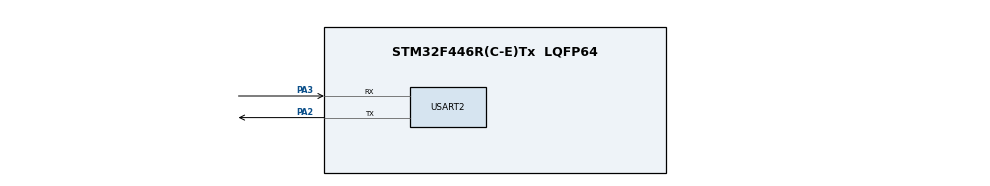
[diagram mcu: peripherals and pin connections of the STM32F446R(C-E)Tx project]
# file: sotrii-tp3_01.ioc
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FREERTOS.Tasks01=defaultTask,24,128,StartDefaultTask,Default,NULL,Dynamic,NULL,NULL
FREERTOS.configCHECK_FOR_STACK_OVERFLOW=0
FREERTOS.configUSE_IDLE_HOOK=0
FREERTOS.configUSE_PREEMPTION=0
FREERTOS.configUSE_TICK_HOOK=0
FREERTOS.configUSE_TIMERS=1
Mcu.Family=STM32F4
Mcu.Name=STM32F446R(C-E)Tx
Mcu.Package=LQFP64
NVIC.PriorityGroup=NVIC_PRIORITYGROUP_4
PA2.Mode=Asynchronous
PA2.Signal=USART2_TX
PA3.Mode=Asynchronous
PA3.Signal=USART2_RX
ProjectManager.HeapSize=0x200
ProjectManager.StackSize=0x400
ProjectManager.TargetToolchain=STM32CubeIDE
RCC.CortexFreq_Value=16000000
RCC.USBFreq_Value=96000000
RCC.VCOOutputFreq_Value=192000000
USART2.VirtualMode=VM_ASYNC
VP_FREERTOS_VS_CMSIS_V2.Mode=CMSIS_V2
VP_TIM6_VS_ClockSourceINT.Mode=Enable_Timer
board=custom

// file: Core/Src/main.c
/* USER CODE BEGIN Header */

/**

******************************************************************************

* @file : main.c

* @brief : Main program body

******************************************************************************

*/

/* USER CODE END Header */
#include "main.h"
#include "cmsis_os.h"

/* USER CODE BEGIN Includes */

#include "app.h"
#include "dwt.h"
#include "logger.h"

/* USER CODE END Includes */

TIM_HandleTypeDef htim6;

UART_HandleTypeDef huart2;

/* Definitions for defaultTask */
osThreadId_t defaultTaskHandle;
const osThreadAttr_t defaultTask_attributes = {
  .name = "defaultTask",
  .stack_size = 128 * 4,
  .priority = (osPriority_t) osPriorityNormal,
};

void SystemClock_Config(void);
static void MX_GPIO_Init(void);
static void MX_TIM6_Init(void);
static void MX_USART2_UART_Init(void);
void StartDefaultTask(void *argument);

/* USER CODE BEGIN PFP */

extern void initialise_monitor_handles(void);

/* USER CODE END PFP */

int main(void)
{

  /* USER CODE BEGIN 1 */
  initialise_monitor_handles();

  /* USER CODE END 1 */

  /* MCU Configuration--------------------------------------------------------*/

  /* Reset of all peripherals, Initializes the Flash interface and the Systick. */
  HAL_Init();

  /* Configure the system clock */
  SystemClock_Config();

  /* USER CODE BEGIN SysInit */

  cycle_counter_init();

  /* USER CODE END SysInit */

  /* Initialize all configured peripherals */
  MX_GPIO_Init();
  MX_TIM6_Init();
  MX_USART2_UART_Init();

  /* Init scheduler */
  osKernelInitialize();

  /* Create the thread(s) */
  /* creation of defaultTask */
  defaultTaskHandle = osThreadNew(StartDefaultTask, NULL, &defaultTask_attributes);

  /* USER CODE BEGIN RTOS_THREADS */

/* Inicialización de la aplicación y creación de la tarea Benchmark Runner */

  app_init();

  /* USER CODE END RTOS_THREADS */

  /* Start scheduler */
  osKernelStart();

  /* We should never get here as control is now taken by the scheduler */

  /* Infinite loop */
while (1)
{

}
}

void SystemClock_Config(void)
{
  RCC_OscInitTypeDef RCC_OscInitStruct = {0};
  RCC_ClkInitTypeDef RCC_ClkInitStruct = {0};

  /** Configure the main internal regulator output voltage
  */
  __HAL_RCC_PWR_CLK_ENABLE();
  __HAL_PWR_VOLTAGESCALING_CONFIG(PWR_REGULATOR_VOLTAGE_SCALE3);

  /** Initializes the RCC Oscillators according to the specified parameters
  * in the RCC_OscInitTypeDef structure.
  */
  RCC_OscInitStruct.OscillatorType = RCC_OSCILLATORTYPE_HSI;
  RCC_OscInitStruct.HSIState = RCC_HSI_ON;
  RCC_OscInitStruct.HSICalibrationValue = RCC_HSICALIBRATION_DEFAULT;
  RCC_OscInitStruct.PLL.PLLState = RCC_PLL_NONE;
  if (HAL_RCC_OscConfig(&RCC_OscInitStruct) != HAL_OK)
  {
    Error_Handler();
  }

  /** Initializes the CPU, AHB and APB buses clocks
  */
  RCC_ClkInitStruct.ClockType = RCC_CLOCKTYPE_HCLK|RCC_CLOCKTYPE_SYSCLK
                              |RCC_CLOCKTYPE_PCLK1|RCC_CLOCKTYPE_PCLK2;
  RCC_ClkInitStruct.SYSCLKSource = RCC_SYSCLKSOURCE_HSI;
  RCC_ClkInitStruct.AHBCLKDivider = RCC_SYSCLK_DIV1;
  RCC_ClkInitStruct.APB1CLKDivider = RCC_HCLK_DIV1;
  RCC_ClkInitStruct.APB2CLKDivider = RCC_HCLK_DIV1;

  if (HAL_RCC_ClockConfig(&RCC_ClkInitStruct, FLASH_LATENCY_0) != HAL_OK)
  {
    Error_Handler();
  }
}

static void MX_TIM6_Init(void)
{

  TIM_MasterConfigTypeDef sMasterConfig = {0};

  htim6.Instance = TIM6;
  htim6.Init.Prescaler = 0;
  htim6.Init.CounterMode = TIM_COUNTERMODE_UP;
  htim6.Init.Period = 65535;
  htim6.Init.AutoReloadPreload = TIM_AUTORELOAD_PRELOAD_DISABLE;
  if (HAL_TIM_Base_Init(&htim6) != HAL_OK)
  {
    Error_Handler();
  }
  sMasterConfig.MasterOutputTrigger = TIM_TRGO_RESET;
  sMasterConfig.MasterSlaveMode = TIM_MASTERSLAVEMODE_DISABLE;
  if (HAL_TIMEx_MasterConfigSynchronization(&htim6, &sMasterConfig) != HAL_OK)
  {
    Error_Handler();
  }

}

static void MX_USART2_UART_Init(void)
{

  huart2.Instance = USART2;
  huart2.Init.BaudRate = 115200;
  huart2.Init.WordLength = UART_WORDLENGTH_8B;
  huart2.Init.StopBits = UART_STOPBITS_1;
  huart2.Init.Parity = UART_PARITY_NONE;
  huart2.Init.Mode = UART_MODE_TX_RX;
  huart2.Init.HwFlowCtl = UART_HWCONTROL_NONE;
  huart2.Init.OverSampling = UART_OVERSAMPLING_16;
  if (HAL_UART_Init(&huart2) != HAL_OK)
  {
    Error_Handler();
  }

}

static void MX_GPIO_Init(void)
{

  /* GPIO Ports Clock Enable */
  __HAL_RCC_GPIOA_CLK_ENABLE();

}

void StartDefaultTask(void *argument)
{
  for(;;)
  {
    osDelay(1);
  }
}

void Error_Handler(void)
{
__disable_irq();
while (1)
{
}
}

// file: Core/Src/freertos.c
/* USER CODE BEGIN Header */
/**
  ******************************************************************************
  * File Name          : freertos.c
  * Description        : Code for freertos applications
  ******************************************************************************
  * @attention
  *
  * Copyright (c) 2026 STMicroelectronics.
  * All rights reserved.
  *
  * This software is licensed under terms that can be found in the LICENSE file
  * in the root directory of this software component.
  * If no LICENSE file comes with this software, it is provided AS-IS.
  *
  ******************************************************************************
  */
/* USER CODE END Header */

#include "FreeRTOS.h"
#include "task.h"
#include "main.h"

/* USER CODE BEGIN Includes */
#include "app.h"
#include "logger.h"
/* USER CODE END Includes */

/* USER CODE BEGIN Variables */
uint32_t g_task_idle_cnt = 0;
uint32_t g_app_stack_overflow_cnt = 0;
volatile uint32_t g_app_tick_cnt = 0;
/* USER CODE END Variables */

/* USER CODE BEGIN Application */

void vApplicationIdleHook(void)
{
  /* Update Task Idle Counter */
  g_task_idle_cnt++;
}

void vApplicationTickHook(void)
{
  /* Update Application Tick Counter */
  g_app_tick_cnt++;
}

void vApplicationStackOverflowHook(TaskHandle_t xTask, char *pcTaskName)
{
  (void)xTask;
  (void)pcTaskName;

  g_app_stack_overflow_cnt++;
  LOGGER_INFO("ERROR: Stack Overflow detectado en tarea: %s", pcTaskName);

  taskDISABLE_INTERRUPTS();
  for (;;);
}

/* USER CODE END Application */
